# ipro7 register map
Vendor: intelpro; Series: BTBLE
CPU: ipro7, little endian
Registers are 32-bit, read-write, reset 0x0 unless marked. A register's access mark holds for its fields unless they carry their own. Offsets are from the block's base; [hi:lo] are bit positions; {n}, {i} and the like mark numbered series.

## MCU
Base 0x3000A000
0x00 L1C_CFG0
0x04 hit_cnt_lsb
0x08 hit_cnt_msb
0x0C miss_cnt
0x10 l1c_misc
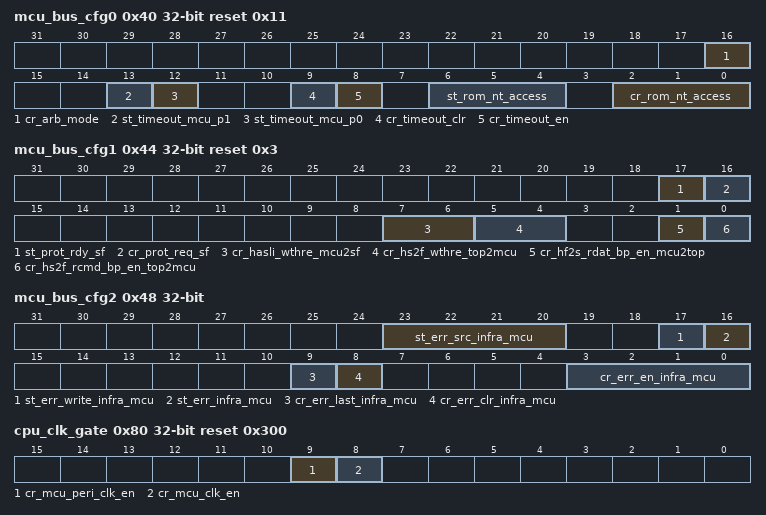
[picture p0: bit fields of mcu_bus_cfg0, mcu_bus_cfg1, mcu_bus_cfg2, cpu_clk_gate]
0x40 mcu_bus_cfg0 reset 0x11 (reset mask 0xFFFFCF8F)
  [16] cr_arb_mode, [13] st_timeout_mcu_p1 ro, [12] st_timeout_mcu_p0 ro, [9] cr_timeout_clr, [8] cr_timeout_en, [6:4] st_rom_nt_access ro, [2:0] cr_rom_nt_access
0x44 mcu_bus_cfg1 reset 0x3 (reset mask 0xFFFDFFFF)
  [17] st_prot_rdy_sf ro, [16] cr_prot_req_sf, [7:6] cr_hasli_wthre_mcu2sf, [5:4] cr_hs2f_wthre_top2mcu, [1] cr_hf2s_rdat_bp_en_mcu2top, [0] cr_hs2f_rcmd_bp_en_top2mcu
0x48 mcu_bus_cfg2 (reset mask 0xFF0CFFFF)
  [23:20] st_err_src_infra_mcu ro, [17] st_err_write_infra_mcu ro, [16] st_err_infra_mcu ro, [9] cr_err_last_infra_mcu, [8] cr_err_clr_infra_mcu, [3:0] cr_err_en_infra_mcu
0x4C mcu_bus_cfg3 reset not defined
  [31:0] st_err_addr_infra_mcu ro
0x50 mcu_bus_cfg4
0x80 cpu_clk_gate reset 0x300
  [9] cr_mcu_peri_clk_en, [8] cr_mcu_clk_en
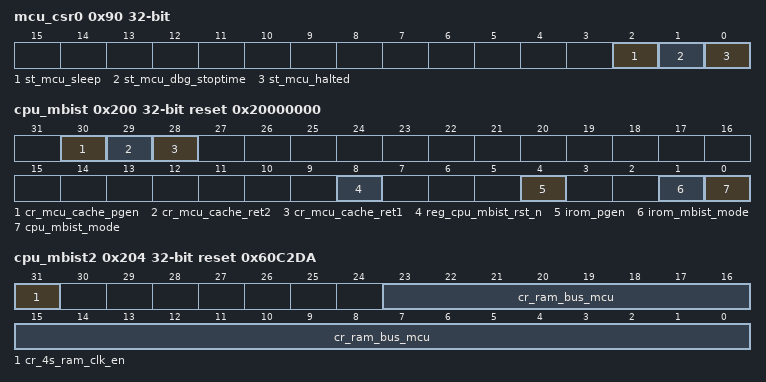
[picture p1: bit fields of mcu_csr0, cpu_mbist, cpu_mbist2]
0x90 mcu_csr0 (reset mask 0xFFFFFFF8)
  [2] st_mcu_sleep ro, [1] st_mcu_dbg_stoptime ro, [0] st_mcu_halted ro
0x200 cpu_mbist reset 0x20000000
  [30] cr_mcu_cache_pgen — CPU Cache Retention
  [29] cr_mcu_cache_ret2 — CPU Cache Sleep
  [28] cr_mcu_cache_ret1 — nap (MCU Cache)
  [8] reg_cpu_mbist_rst_n
  [4] irom_pgen
  [1] irom_mbist_mode
  [0] cpu_mbist_mode
0x204 cpu_mbist2 reset 0x60C2DA
  [31] cr_4s_ram_clk_en
  [23:0] cr_ram_bus_mcu — [23]=rambus[32]=DVSE [22:19]=rambus[31:28]=DVS [18:17]=ram_bus[27:26]=WABLM_SRAM [16:14]=ram_bus[25:23]=EMA_SRAM [13:12]=ram_bus[22:21]=WABLM_RF [11:10]=ram_bus[20:19]=RAWLM [9]=ram_bus[18]=WABL [8]=ram_bus[17]=RAWL [7:7]=ram_bus[16:15]=EMAW [5:3]=ram_bus[14:12]=EMA_RF [2:0]=ram_bus[11:9]=EMA_ROM

## CKS
Base 0x30012000
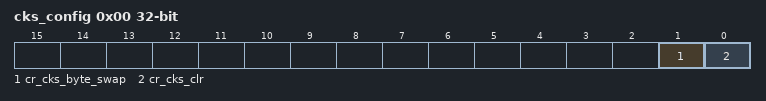
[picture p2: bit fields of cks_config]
0x00 cks_config
  [1] cr_cks_byte_swap — Byte swap signal for each 16-bit data 1'b0: The first data pushed should be the upper byte 1'b1: The first data pushed should be the lower byte
  [0] cr_cks_clr — Checksum clear (reset) signal
0x04 data_in
  [7:0] data_in wo — Data input
0x08 cks_out reset 0xFFFF (reset mask 0xFFFF0000)
  [15:0] cks_out ro — Checksum output

## QDEC0
Base 0x30013000
Same registers: QDEC1 0x30014000, QDEC2 0x30015000
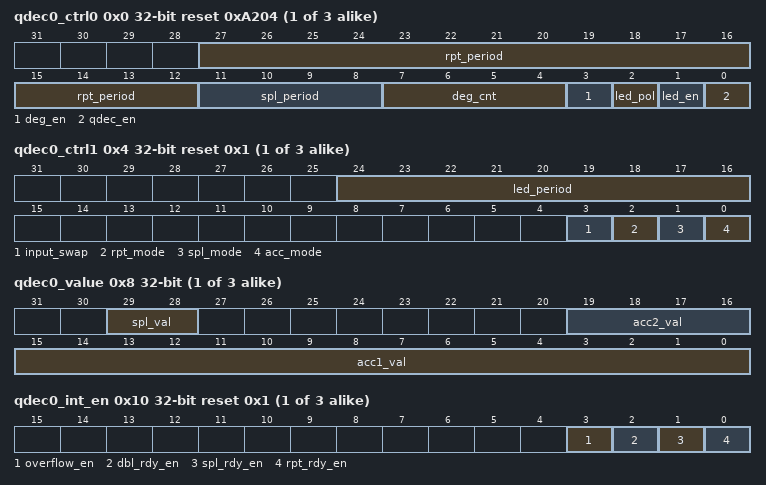
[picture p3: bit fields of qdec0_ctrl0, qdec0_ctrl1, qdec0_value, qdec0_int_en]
{0x0+0x40*i} qdec{i}_ctrl0 reset 0xA204 (i=0..2)
  [27:12] rpt_period — "RPT" report period in [samples/report]. Specifies the number of samples to be accumulated in the ACC1 register before the RPT_RDY and DBL_RDY events can be generated "RPT_US" report period in [us/report] = SP * RP
  [11:8] spl_period — "SPL" sample period in [us/sample]. The SAMPLE register will be updated for every new sample 0: 32 us 1: 64 2: 128 3: 256 4: 512 5: 1 ms 6: 2 7: 4 8: 8 9: 16 A: 32 B: 65 C: 131
  [7:4] deg_cnt
  [3] deg_en — deglitch
  [2] led_pol — led polarity
  [1] led_en
  [0] qdec_en
{0x4+0x40*i} qdec{i}_ctrl1 reset 0x1 (i=0..2)
  [24:16] led_period — Period in us the LED is switched on prior to sampling
  [3] input_swap — input a/b swap
  [2] rpt_mode — rpt option 0: Count time only if sample change 1: Continue time
  [1] spl_mode — spl option 0: Stop sample if rpt_rdy 1: Continue sample
  [0] acc_mode — acc option 0: Stop accumulate if overflow 1: Continue accumulate
{0x8+0x40*i} qdec{i}_value (reset mask 0xCFF00000) (i=0..2)
  [29:28] spl_val ro — Sample value. Direction of last change 00: no change 01: clockwise 11: counter-clockwise 10: Error
  [19:16] acc2_val ro — Double error accumulation (0~15)
  [15:0] acc1_val ro — Sample accumulation (-1024~1023)
{0x10+0x40*i} qdec{i}_int_en reset 0x1 (i=0..2)
  [3] overflow_en, [2] dbl_rdy_en, [1] spl_rdy_en, [0] rpt_rdy_en
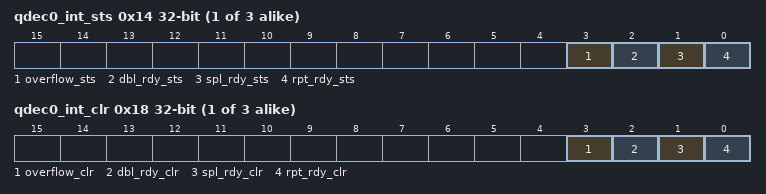
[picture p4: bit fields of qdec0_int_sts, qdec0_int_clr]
{0x14+0x40*i} qdec{i}_int_sts (reset mask 0xFFFFFFF0) (i=0..2)
  [3] overflow_sts ro — ACC1 or ACC2 overflow
  [2] dbl_rdy_sts ro — ACC2 double error
  [1] spl_rdy_sts ro — Event being generated for every new sample value written to the SAMPLE register
  [0] rpt_rdy_sts ro — Non-null report ready
{0x18+0x40*i} qdec{i}_int_clr (i=0..2)
  [3] overflow_clr, [2] dbl_rdy_clr, [1] spl_rdy_clr, [0] rpt_rdy_clr
